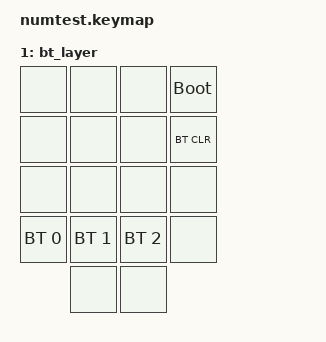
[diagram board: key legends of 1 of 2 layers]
/*
 * Copyright (c) 2021 The ZMK Contributors
 *
 * SPDX-License-Identifier: MIT
 */

#include <behaviors.dtsi>
#include <dt-bindings/zmk/keys.h>
#include <dt-bindings/zmk/bt.h>



/ {
    keymap {
        compatible = "zmk,keymap";

        default_layer {


            bindings = <
                &mo 1         &kp KP_DIVIDE  &kp KP_MULTIPLY   &kp KP_MINUS
				&kp KP_N7     &kp KP_N8      &kp KP_N9         &kp KP_PLUS
				&kp KP_N4     &kp KP_N5      &kp KP_N6
				&kp KP_N1     &kp KP_N2      &kp KP_N3         &kp KP_ENTER
							  &kp KP_N0      &kp KP_DOT 
            >;
        };

        bt_layer {

            bindings = <
                &none    	  &none       		&none      		&bootloader 
                &none    	  &none       		&none      		&bt BT_CLR   
                &none  	 	  &none       		&none      		&none  
                &bt BT_SEL 0  &bt BT_SEL 1      &bt BT_SEL 2    &none 
							  &none   			&none    
            >;
        };



    };
};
